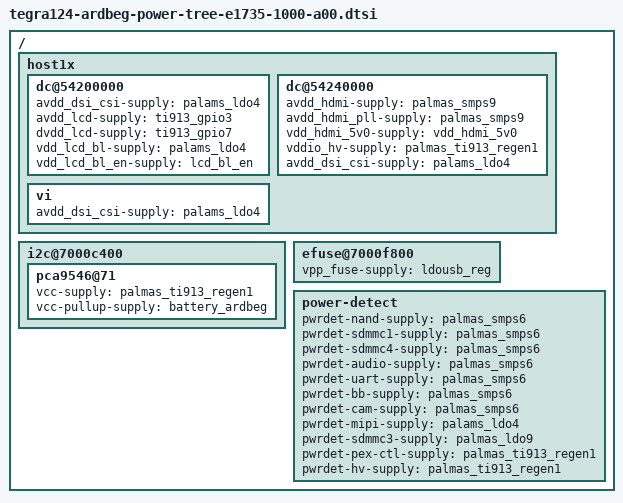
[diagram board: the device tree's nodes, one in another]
#include "tegra124-platforms/tegra124-ardbeg-pmic-e1735-1000-a00.dtsi"
#include "tegra124-platforms/tegra124-ardbeg-fixed-e1735-1000-a00.dtsi"

/ {
	host1x {
		/* tegradc.0 */
		dc@54200000 {
			avdd_dsi_csi-supply = <&palams_ldo4>;
			avdd_lcd-supply = <&ti913_gpio3>;
			dvdd_lcd-supply = <&ti913_gpio7>;
			vdd_lcd_bl-supply = <&palams_ldo4>;
			vdd_lcd_bl_en-supply = <&lcd_bl_en>;
		};

		/* tegradc.1 */
		dc@54240000 {
			avdd_hdmi-supply = <&palmas_smps9>;
			avdd_hdmi_pll-supply = <&palmas_smps9>;
			vdd_hdmi_5v0-supply = <&vdd_hdmi_5v0>;
			vddio_hv-supply = <&palmas_ti913_regen1>;
			avdd_dsi_csi-supply = <&palams_ldo4>;
		};

		vi {
			avdd_dsi_csi-supply = <&palams_ldo4>;
		};
	};

	i2c@7000c400 {
		pca9546@71 {
			vcc-supply = <&palmas_ti913_regen1>;
			vcc-pullup-supply = <&battery_ardbeg>;
		};
	};

	efuse@7000f800 {
		vpp_fuse-supply = <&ldousb_reg>;
	};

	power-detect {
		pwrdet-nand-supply = <&palmas_smps6>;
		pwrdet-sdmmc1-supply = <&palmas_smps6>;
		pwrdet-sdmmc4-supply = <&palmas_smps6>;
		pwrdet-audio-supply = <&palmas_smps6>;
		pwrdet-uart-supply = <&palmas_smps6>;
		pwrdet-bb-supply = <&palmas_smps6>;
		pwrdet-cam-supply = <&palmas_smps6>;
		pwrdet-mipi-supply = <&palams_ldo4>;
		pwrdet-sdmmc3-supply = <&palmas_ldo9>;
		pwrdet-pex-ctl-supply = <&palmas_ti913_regen1>;
		pwrdet-hv-supply = <&palmas_ti913_regen1>;
	};
};
